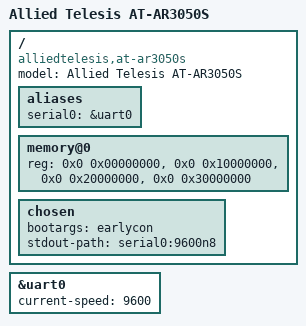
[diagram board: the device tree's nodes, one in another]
// SPDX-License-Identifier: GPL-2.0-or-later OR MIT

#include "cn71xx.dtsi"

#include <dt-bindings/gpio/gpio.h>
#include <dt-bindings/input/input.h>
#include <dt-bindings/interrupt-controller/irq.h>

/ {
	compatible = "alliedtelesis,at-ar3050s", "cavium,cn7020";
	model = "Allied Telesis AT-AR3050S";

	aliases {
		serial0 = &uart0;
/*		led-boot =
		led-failsafe =
		led-running =
		led-upgrade =
*/	};

	memory@0 {
		device_type = "memory";
		reg = <0x0 0x00000000>,
		      <0x0 0x10000000>,
		      <0x0 0x20000000>,
		      <0x0 0x30000000>;
	};

	chosen {
		bootargs = "earlycon";
		stdout-path = "serial0:9600n8";
	};
};

&uart0 {
	status = "okay";

	current-speed = <9600>;
};
